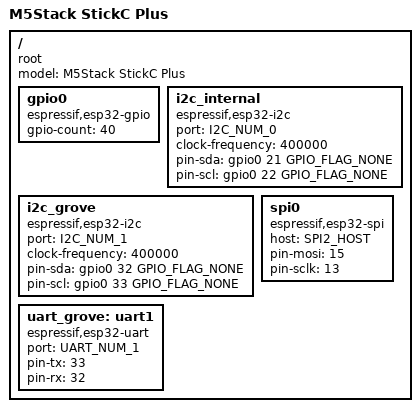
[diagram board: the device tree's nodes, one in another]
/dts-v1/;

#include <tactility/bindings/root.h>
#include <tactility/bindings/esp32_gpio.h>
#include <tactility/bindings/esp32_i2c.h>
#include <tactility/bindings/esp32_spi.h>
#include <tactility/bindings/esp32_uart.h>

/ {
	compatible = "root";
	model = "M5Stack StickC Plus";

	gpio0 {
		compatible = "espressif,esp32-gpio";
		gpio-count = <40>;
	};

	i2c_internal {
		compatible = "espressif,esp32-i2c";
		port = <I2C_NUM_0>;
		clock-frequency = <400000>;
		pin-sda = <&gpio0 21 GPIO_FLAG_NONE>;
		pin-scl = <&gpio0 22 GPIO_FLAG_NONE>;
	};

	i2c_grove {
		compatible = "espressif,esp32-i2c";
		port = <I2C_NUM_1>;
		clock-frequency = <400000>;
		pin-sda = <&gpio0 32 GPIO_FLAG_NONE>;
		pin-scl = <&gpio0 33 GPIO_FLAG_NONE>;
	};

	spi0 {
		compatible = "espressif,esp32-spi";
		host = <SPI2_HOST>;
		pin-mosi = <15>;
		pin-sclk = <13>;
	};

	uart_grove: uart1 {
		compatible = "espressif,esp32-uart";
		port = <UART_NUM_1>;
		pin-tx = <33>;
		pin-rx = <32>;
	};
};
